# PIC18F45Q71 register map
Vendor: Microchip
Registers are 8-bit, read-write, reset 0x0 unless marked. A register's access mark holds for its fields unless they carry their own. Addresses are absolute, and some are shared; only a register's first bit layout is shown; [hi:lo] are bit positions; {n}, {i} and the like mark numbered series.

## tmr_dds
0x440 NCO1ACCL
  [7:0] ACC
0x441 NCO1ACCH
  [7:0] ACC
0x442 NCO1ACCU
  [3:0] ACC
0x443 NCO1INCL reset 0x1
  [7:0] INC
0x444 NCO1INCH
  [7:0] INC
0x445 NCO1INCU
  [3:0] INC
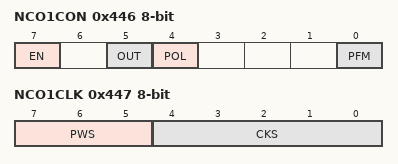
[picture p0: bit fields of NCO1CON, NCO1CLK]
0x446 NCO1CON — Configurable logic cell control
  [7] EN, [5] OUT ro, [4] POL, [0] PFM
0x447 NCO1CLK
  [7:5] PWS, [4:0] CKS

## int
0x459 IVTLOCK
  [0] IVTLOCKED
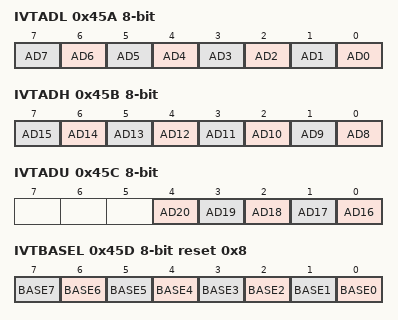
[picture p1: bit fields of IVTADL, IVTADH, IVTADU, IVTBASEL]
0x45A IVTADL
  [n] AD{n} (n=0..7)
0x45B IVTADH
  [n-8] AD{n} (n=8..15)
0x45C IVTADU
  [n-16] AD{n} (n=16..20)
0x45D IVTBASEL reset 0x8
  [n] BASE{n} (n=0..7)
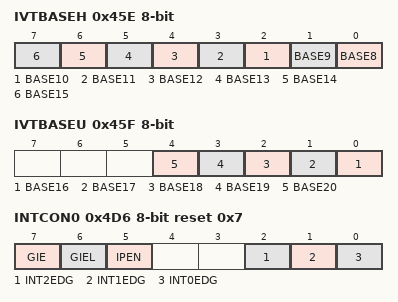
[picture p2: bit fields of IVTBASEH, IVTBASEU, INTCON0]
0x45E IVTBASEH
  [n-8] BASE{n} (n=8..15)
0x45F IVTBASEU
  [n-16] BASE{n} (n=16..20)
0x4D6 INTCON0 reset 0x7
  [7] GIE, [6] GIEL, [5] IPEN, [2] INT2EDG, [1] INT1EDG, [0] INT0EDG
0x4D7 INTCON1 ro
  [7:6] STAT

## pwm_cmp
0x460 PWM1ERS
  [3:0] ERS
0x461 PWM1CLK
  [4:0] CLK
0x462 PWM1LDS
  [3:0] LDS
{0x454+0xF*i} PWM{i}PRL (i=1..3)
  [7:0] PRL
{0x455+0xF*i} PWM{i}PRH (i=1..3)
  [7:0] PRH
{0x456+0xF*i} PWM{i}CPRE (i=1..3)
  [7:0] CPRE
{0x457+0xF*i} PWM{i}PIPOS (i=1..3)
  [7:0] PIPOS
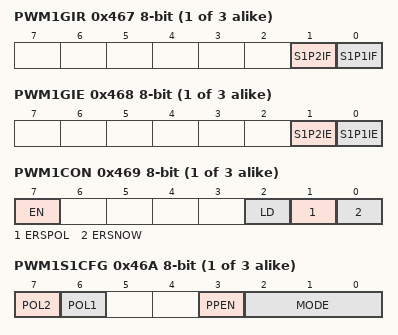
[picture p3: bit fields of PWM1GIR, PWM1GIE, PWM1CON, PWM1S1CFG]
{0x458+0xF*i} PWM{i}GIR (i=1..3)
  [1] S1P2IF, [0] S1P1IF
{0x459+0xF*i} PWM{i}GIE (i=1..3)
  [1] S1P2IE, [0] S1P1IE
{0x45A+0xF*i} PWM{i}CON (i=1..3)
  [7] EN, [2] LD, [1] ERSPOL, [0] ERSNOW
{0x45B+0xF*i} PWM{i}S1CFG (i=1..3)
  [7] POL2, [6] POL1, [3] PPEN, [2:0] MODE
{0x45C+0xF*i} PWM{i}S1P1L (i=1..3)
  [7:0] S1P1L
{0x45D+0xF*i} PWM{i}S1P1H (i=1..3)
  [7:0] S1P1H
{0x45E+0xF*i} PWM{i}S1P2L (i=1..3)
  [7:0] S1P2L
{0x45F+0xF*i} PWM{i}S1P2H (i=1..3)
  [7:0] S1P2H
0x46F PWM2ERS
  [7:0] ERS
0x470 PWM2CLK
  [7:0] CLK
0x471 PWM2LDS
  [7:0] LDS
0x47E PWM3ERS
  [7:0] ERS
0x47F PWM3CLK
  [7:0] CLK
0x480 PWM3LDS
  [7:0] LDS

## DOS_xxxx_Interrupts
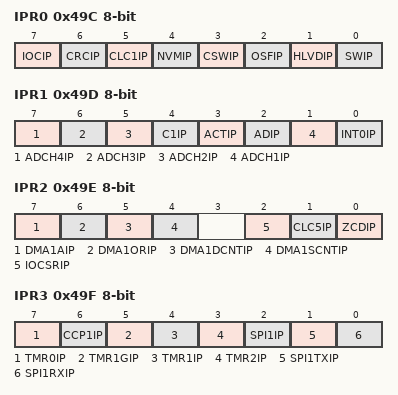
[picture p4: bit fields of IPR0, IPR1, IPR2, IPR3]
0x49C IPR0
  [7] IOCIP ro, [6] CRCIP, [5] CLC1IP, [4] NVMIP, [3] CSWIP, [2] OSFIP ro, [1] HLVDIP, [0] SWIP
0x49D IPR1
  [7] ADCH4IP, [6] ADCH3IP, [5] ADCH2IP, [4] C1IP, [3] ACTIP, [2] ADIP, [1] ADCH1IP, [0] INT0IP
0x49E IPR2
  [7] DMA1AIP, [6] DMA1ORIP, [5] DMA1DCNTIP, [4] DMA1SCNTIP, [2] IOCSRIP, [1] CLC5IP, [0] ZCDIP
0x49F IPR3
  [7] TMR0IP, [6] CCP1IP, [5] TMR1GIP, [4] TMR1IP, [3] TMR2IP, [2] SPI1IP ro, [1] SPI1TXIP ro, [0] SPI1RXIP ro
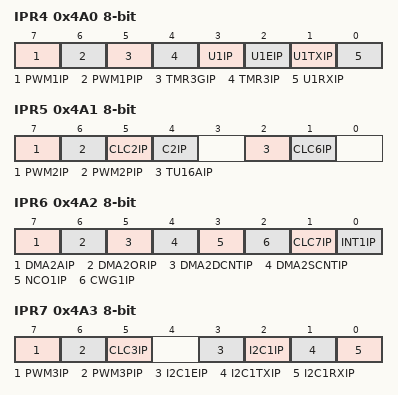
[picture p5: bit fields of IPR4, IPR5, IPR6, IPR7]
0x4A0 IPR4
  [7] PWM1IP ro, [6] PWM1PIP, [5] TMR3GIP, [4] TMR3IP, [3] U1IP ro, [2] U1EIP ro, [1] U1TXIP ro, [0] U1RXIP ro
0x4A1 IPR5
  [7] PWM2IP ro, [6] PWM2PIP, [5] CLC2IP, [4] C2IP, [2] TU16AIP ro, [1] CLC6IP
0x4A2 IPR6
  [7] DMA2AIP, [6] DMA2ORIP, [5] DMA2DCNTIP, [4] DMA2SCNTIP, [3] NCO1IP, [2] CWG1IP, [1] CLC7IP, [0] INT1IP
0x4A3 IPR7
  [7] PWM3IP ro, [6] PWM3PIP, [5] CLC3IP, [3] I2C1EIP ro, [2] I2C1IP ro, [1] I2C1TXIP ro, [0] I2C1RXIP ro
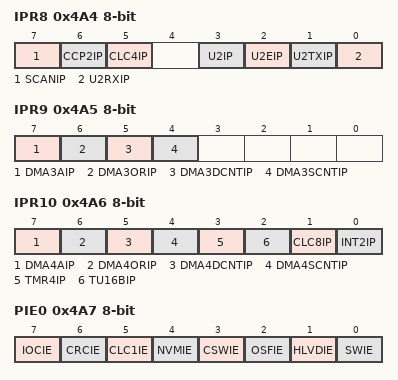
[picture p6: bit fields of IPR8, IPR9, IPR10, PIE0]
0x4A4 IPR8
  [7] SCANIP ro, [6] CCP2IP, [5] CLC4IP, [3] U2IP ro, [2] U2EIP ro, [1] U2TXIP ro, [0] U2RXIP ro
0x4A5 IPR9
  [7] DMA3AIP, [6] DMA3ORIP, [5] DMA3DCNTIP, [4] DMA3SCNTIP
0x4A6 IPR10
  [7] DMA4AIP, [6] DMA4ORIP, [5] DMA4DCNTIP, [4] DMA4SCNTIP, [3] TMR4IP, [2] TU16BIP ro, [1] CLC8IP, [0] INT2IP
0x4A7 PIE0
  [7] IOCIE ro, [6] CRCIE, [5] CLC1IE, [4] NVMIE, [3] CSWIE, [2] OSFIE ro, [1] HLVDIE, [0] SWIE
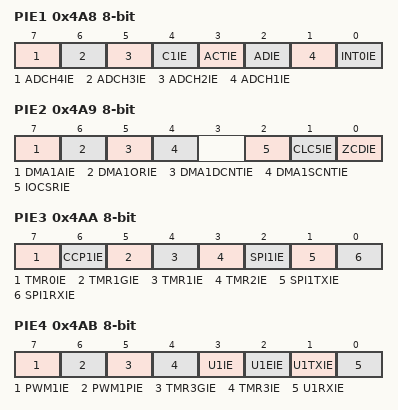
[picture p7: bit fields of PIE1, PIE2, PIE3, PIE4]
0x4A8 PIE1
  [7] ADCH4IE, [6] ADCH3IE, [5] ADCH2IE, [4] C1IE, [3] ACTIE, [2] ADIE, [1] ADCH1IE, [0] INT0IE
0x4A9 PIE2
  [7] DMA1AIE, [6] DMA1ORIE, [5] DMA1DCNTIE, [4] DMA1SCNTIE, [2] IOCSRIE, [1] CLC5IE, [0] ZCDIE
0x4AA PIE3
  [7] TMR0IE, [6] CCP1IE, [5] TMR1GIE, [4] TMR1IE, [3] TMR2IE, [2] SPI1IE ro, [1] SPI1TXIE ro, [0] SPI1RXIE ro
0x4AB PIE4
  [7] PWM1IE ro, [6] PWM1PIE, [5] TMR3GIE, [4] TMR3IE, [3] U1IE ro, [2] U1EIE ro, [1] U1TXIE ro, [0] U1RXIE ro
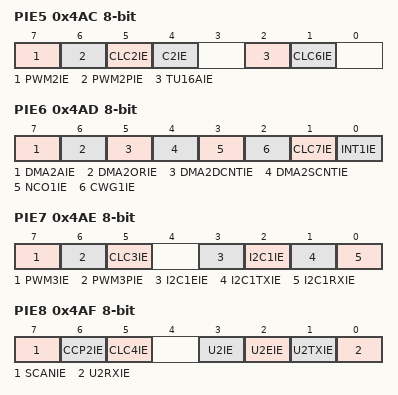
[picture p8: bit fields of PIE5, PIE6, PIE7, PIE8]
0x4AC PIE5
  [7] PWM2IE ro, [6] PWM2PIE, [5] CLC2IE, [4] C2IE, [2] TU16AIE ro, [1] CLC6IE
0x4AD PIE6
  [7] DMA2AIE, [6] DMA2ORIE, [5] DMA2DCNTIE, [4] DMA2SCNTIE, [3] NCO1IE, [2] CWG1IE, [1] CLC7IE, [0] INT1IE
0x4AE PIE7
  [7] PWM3IE ro, [6] PWM3PIE, [5] CLC3IE, [3] I2C1EIE ro, [2] I2C1IE ro, [1] I2C1TXIE ro, [0] I2C1RXIE ro
0x4AF PIE8
  [7] SCANIE ro, [6] CCP2IE, [5] CLC4IE, [3] U2IE ro, [2] U2EIE ro, [1] U2TXIE ro, [0] U2RXIE ro
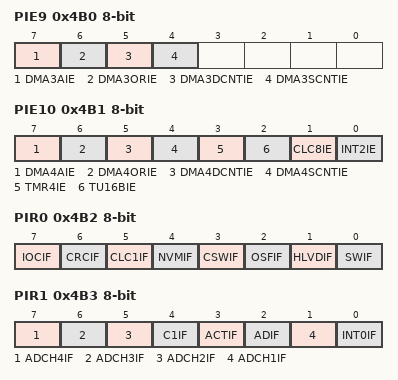
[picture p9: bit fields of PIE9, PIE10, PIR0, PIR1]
0x4B0 PIE9
  [7] DMA3AIE, [6] DMA3ORIE, [5] DMA3DCNTIE, [4] DMA3SCNTIE
0x4B1 PIE10
  [7] DMA4AIE, [6] DMA4ORIE, [5] DMA4DCNTIE, [4] DMA4SCNTIE, [3] TMR4IE, [2] TU16BIE ro, [1] CLC8IE, [0] INT2IE
0x4B2 PIR0
  [7] IOCIF ro, [6] CRCIF, [5] CLC1IF, [4] NVMIF, [3] CSWIF, [2] OSFIF ro, [1] HLVDIF, [0] SWIF
0x4B3 PIR1
  [7] ADCH4IF, [6] ADCH3IF, [5] ADCH2IF, [4] C1IF, [3] ACTIF, [2] ADIF, [1] ADCH1IF, [0] INT0IF
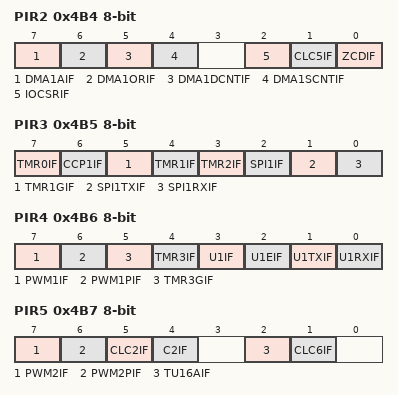
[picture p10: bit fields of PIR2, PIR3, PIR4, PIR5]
0x4B4 PIR2
  [7] DMA1AIF, [6] DMA1ORIF, [5] DMA1DCNTIF, [4] DMA1SCNTIF, [2] IOCSRIF, [1] CLC5IF, [0] ZCDIF
0x4B5 PIR3
  [7] TMR0IF, [6] CCP1IF, [5] TMR1GIF, [4] TMR1IF, [3] TMR2IF, [2] SPI1IF ro, [1] SPI1TXIF ro, [0] SPI1RXIF ro
0x4B6 PIR4
  [7] PWM1IF ro, [6] PWM1PIF, [5] TMR3GIF, [4] TMR3IF, [3] U1IF ro, [2] U1EIF ro, [1] U1TXIF ro, [0] U1RXIF ro
0x4B7 PIR5
  [7] PWM2IF ro, [6] PWM2PIF, [5] CLC2IF, [4] C2IF, [2] TU16AIF ro, [1] CLC6IF
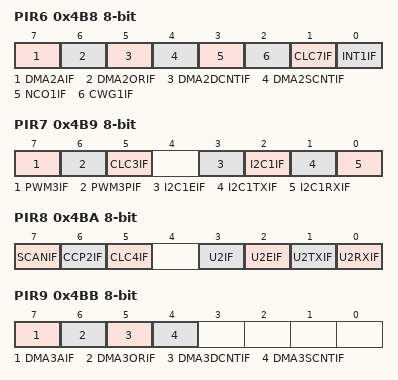
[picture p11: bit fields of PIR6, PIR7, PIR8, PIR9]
0x4B8 PIR6
  [7] DMA2AIF, [6] DMA2ORIF, [5] DMA2DCNTIF, [4] DMA2SCNTIF, [3] NCO1IF, [2] CWG1IF, [1] CLC7IF, [0] INT1IF
0x4B9 PIR7
  [7] PWM3IF ro, [6] PWM3PIF, [5] CLC3IF, [3] I2C1EIF ro, [2] I2C1IF ro, [1] I2C1TXIF ro, [0] I2C1RXIF ro
0x4BA PIR8
  [7] SCANIF ro, [6] CCP2IF, [5] CLC4IF, [3] U2IF ro, [2] U2EIF ro, [1] U2TXIF ro, [0] U2RXIF ro
0x4BB PIR9
  [7] DMA3AIF, [6] DMA3ORIF, [5] DMA3DCNTIF, [4] DMA3SCNTIF
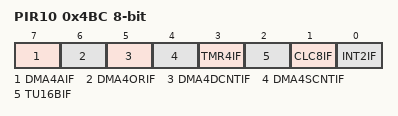
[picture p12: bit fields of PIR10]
0x4BC PIR10
  [7] DMA4AIF, [6] DMA4ORIF, [5] DMA4DCNTIF, [4] DMA4SCNTIF, [3] TMR4IF, [2] TU16BIF ro, [1] CLC8IF, [0] INT2IF
